AUTOSAR XML (schema 4-0-3)
standard types defined: Boolean, UInt32
package /AUTOSAR_Platform/DataConstrs
  range DC_Boolean: raw 0..1
package /PATAC/MSM/ComponentTypes
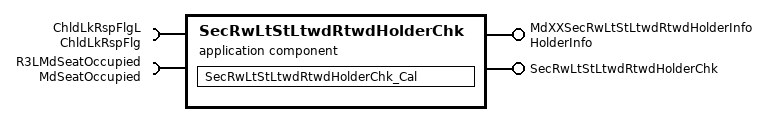
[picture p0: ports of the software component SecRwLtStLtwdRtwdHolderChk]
  application sw component type SecRwLtStLtwdRtwdHolderChk
    provide port MdXXSecRwLtStLtwdRtwdHolderInfo: nonqueued-sender-com-spec{data-element=HolderInfo/Val, init-value=0}, provided-interface=HolderInfo
    provide port SecRwLtStLtwdRtwdHolderChk: server-com-spec{operation=Cal, queue-length=1}, provided-interface=SecRwLtStLtwdRtwdHolderChk
    require port ChldLkRspFlgL: nonqueued-receiver-com-spec{data-element=ChldLkRspFlg/Val, filter=data-filter-type=ALWAYS, init-value=0}, required-interface=ChldLkRspFlg
    require port R3LMdSeatOccupied: nonqueued-receiver-com-spec{data-element=MdSeatOccupied/Val, filter=data-filter-type=ALWAYS, init-value=0}, required-interface=MdSeatOccupied
    behavior SecRwLtStLtwdRtwdHolderChk_InternalBehavior
      operation invoked event OIT_SecRwLtStLtwdRtwdHolderChk_Cal_SecRwLtStLtwdRtwdHolderChk_Cal: start-on-event=SecRwLtStLtwdRtwdHolderChk_Cal, operation=SecRwLtStLtwdRtwdHolderChk.Cal
      runnable SecRwLtStLtwdRtwdHolderChk_Cal
        data-receive-point-by-arguments:
          access REC_ChldLkRspFlgL_Val: accessed-variable=ChldLkRspFlgL.Val
          access REC_R3LMdSeatOccupied_Val: accessed-variable=R3LMdSeatOccupied.Val
        data-send-points:
          access SEND_MdXXSecRwLtStLtwdRtwdHolderInfo_Val: accessed-variable=MdXXSecRwLtStLtwdRtwdHolderInfo.Val
  swc implementation SecRwLtStLtwdRtwdHolderChk_Implementation: behavior=SecRwLtStLtwdRtwdHolderChk_InternalBehavior
    code-descriptors:
      code Default: artifact-descriptors=autosar-engineering-object={short-label=Default, category=SWSRC}
package /PATAC/MSM/ModeAdjust/PortInterface
  client server interface SecRwLtStLtwdRtwdHolderChk
    operation Cal
  sender receiver interface ChldLkRspFlg: invalidation-policy{data-element=ChldLkRspFlg/Val, handle-invalid=DONT-INVALIDATE}
    data Val: type=Boolean
  sender receiver interface HolderInfo: invalidation-policy{data-element=HolderInfo/Val, handle-invalid=DONT-INVALIDATE}
    data Val: type=UInt32
  sender receiver interface MdSeatOccupied: invalidation-policy{data-element=MdSeatOccupied/Val, handle-invalid=DONT-INVALIDATE}
    data Val: type=Boolean
